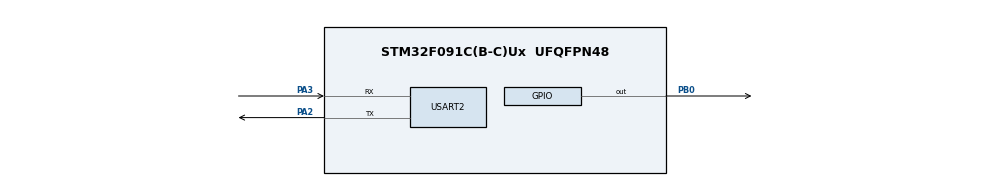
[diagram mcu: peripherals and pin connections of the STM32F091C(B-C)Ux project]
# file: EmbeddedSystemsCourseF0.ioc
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FREERTOS.INCLUDE_vTaskDelayUntil=1
FREERTOS.Tasks01=defaultTask,0,128,startDefaultTask,Default,NULL,Dynamic,NULL,NULL
FREERTOS.Timers01=periodicTimer,periodicTimerCallback,osTimerPeriodic,Default,NULL,Dynamic,NULL;OneShotTimer,OneShotTimerCallback,osTimerOnce,Default,NULL,Dynamic,NULL
FREERTOS.configUSE_IDLE_HOOK=1
FREERTOS.configUSE_NEWLIB_REENTRANT=1
FREERTOS.configUSE_TIMERS=1
Mcu.Family=STM32F0
Mcu.Name=STM32F091C(B-C)Ux
Mcu.Package=UFQFPN48
NVIC.TIM6_DAC_IRQn=true\:3\:0\:false\:false\:true\:false\:false\:true\:true
NVIC.TimeBase=TIM6_DAC_IRQn
NVIC.TimeBaseIP=TIM6
PA2.Mode=Asynchronous
PA2.Signal=USART2_TX
PA3.Mode=Asynchronous
PA3.Signal=USART2_RX
PB0.Signal=GPIO_Output
ProjectManager.HeapSize=0x200
ProjectManager.StackSize=0x400
ProjectManager.TargetToolchain=STM32CubeIDE
USART2.VirtualMode-Asynchronous=VM_ASYNC
VP_FREERTOS_VS_CMSIS_V1.Mode=CMSIS_V1
VP_SYS_VS_tim6.Mode=TIM6
board=custom

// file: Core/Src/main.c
/* USER CODE BEGIN Header */
/**
 ******************************************************************************
 * @file           : main.c
 * @brief          : Main program body
 ******************************************************************************
 * @attention
 *
 * Copyright (c) 2025 STMicroelectronics.
 * All rights reserved.
 *
 * This software is licensed under terms that can be found in the LICENSE file
 * in the root directory of this software component.
 * If no LICENSE file comes with this software, it is provided AS-IS.
 *
 ******************************************************************************
 */
/* USER CODE END Header */
#include "main.h"
#include "cmsis_os.h"

/* USER CODE BEGIN Includes */
#include <stdio.h>
/* USER CODE END Includes */

UART_HandleTypeDef huart2;

osThreadId defaultTaskHandle;
osTimerId periodicTimerHandle;
osTimerId OneShotTimerHandle;
/* USER CODE BEGIN PV */
uint32_t indx = 0;
/* USER CODE END PV */

void SystemClock_Config(void);
static void MX_GPIO_Init(void);
static void MX_USART2_UART_Init(void);
void startDefaultTask(void const * argument);
void periodicTimerCallback(void const * argument);
void OneShotTimerCallback(void const * argument);

/* USER CODE BEGIN PFP */
/*To make printf() work over UART in STM32, we override(Redirected to UART)*/
int _write(int file, char *ptr, int len) {
	HAL_UART_Transmit(&huart2, (uint8_t*) ptr, len, 100);
	return len;
}
/* USER CODE END PFP */

int main(void)
{

  /* MCU Configuration--------------------------------------------------------*/

  /* Reset of all peripherals, Initializes the Flash interface and the Systick. */
  HAL_Init();

  /* Configure the system clock */
  SystemClock_Config();

  /* Initialize all configured peripherals */
  MX_GPIO_Init();
  MX_USART2_UART_Init();

  /* Create the timer(s) */
  /* definition and creation of periodicTimer */
  osTimerDef(periodicTimer, periodicTimerCallback);
  periodicTimerHandle = osTimerCreate(osTimer(periodicTimer), osTimerPeriodic, NULL);

  /* definition and creation of OneShotTimer */
  osTimerDef(OneShotTimer, OneShotTimerCallback);
  OneShotTimerHandle = osTimerCreate(osTimer(OneShotTimer), osTimerOnce, NULL);

  /* USER CODE BEGIN RTOS_TIMERS */
	/* start timers, add new ones, ... */
  /*Start the Timers*/
      if (OneShotTimerHandle != NULL) {
          osTimerStart(OneShotTimerHandle, 2000);  // 2000ms = 2s
      }

      if (periodicTimerHandle != NULL) {
          osTimerStart(periodicTimerHandle, 500);  // 500ms
      }
  /* USER CODE END RTOS_TIMERS */

  /* Create the thread(s) */
  /* definition and creation of defaultTask */
  osThreadDef(defaultTask, startDefaultTask, osPriorityNormal, 0, 128);
  defaultTaskHandle = osThreadCreate(osThread(defaultTask), NULL);

  /* Start scheduler */
  osKernelStart();

  /* We should never get here as control is now taken by the scheduler */
  /* Infinite loop */
	while (1) {

	}
}

void SystemClock_Config(void)
{
  RCC_OscInitTypeDef RCC_OscInitStruct = {0};
  RCC_ClkInitTypeDef RCC_ClkInitStruct = {0};
  RCC_PeriphCLKInitTypeDef PeriphClkInit = {0};

  /** Initializes the RCC Oscillators according to the specified parameters
  * in the RCC_OscInitTypeDef structure.
  */
  RCC_OscInitStruct.OscillatorType = RCC_OSCILLATORTYPE_HSI;
  RCC_OscInitStruct.HSIState = RCC_HSI_ON;
  RCC_OscInitStruct.HSICalibrationValue = RCC_HSICALIBRATION_DEFAULT;
  RCC_OscInitStruct.PLL.PLLState = RCC_PLL_NONE;
  if (HAL_RCC_OscConfig(&RCC_OscInitStruct) != HAL_OK)
  {
    Error_Handler();
  }

  /** Initializes the CPU, AHB and APB buses clocks
  */
  RCC_ClkInitStruct.ClockType = RCC_CLOCKTYPE_HCLK|RCC_CLOCKTYPE_SYSCLK
                              |RCC_CLOCKTYPE_PCLK1;
  RCC_ClkInitStruct.SYSCLKSource = RCC_SYSCLKSOURCE_HSI;
  RCC_ClkInitStruct.AHBCLKDivider = RCC_SYSCLK_DIV1;
  RCC_ClkInitStruct.APB1CLKDivider = RCC_HCLK_DIV1;

  if (HAL_RCC_ClockConfig(&RCC_ClkInitStruct, FLASH_LATENCY_0) != HAL_OK)
  {
    Error_Handler();
  }
  PeriphClkInit.PeriphClockSelection = RCC_PERIPHCLK_USART2;
  PeriphClkInit.Usart2ClockSelection = RCC_USART2CLKSOURCE_PCLK1;
  if (HAL_RCCEx_PeriphCLKConfig(&PeriphClkInit) != HAL_OK)
  {
    Error_Handler();
  }
}

static void MX_USART2_UART_Init(void)
{

  huart2.Instance = USART2;
  huart2.Init.BaudRate = 115200;
  huart2.Init.WordLength = UART_WORDLENGTH_8B;
  huart2.Init.StopBits = UART_STOPBITS_1;
  huart2.Init.Parity = UART_PARITY_NONE;
  huart2.Init.Mode = UART_MODE_TX_RX;
  huart2.Init.HwFlowCtl = UART_HWCONTROL_NONE;
  huart2.Init.OverSampling = UART_OVERSAMPLING_16;
  huart2.Init.OneBitSampling = UART_ONE_BIT_SAMPLE_DISABLE;
  huart2.AdvancedInit.AdvFeatureInit = UART_ADVFEATURE_NO_INIT;
  if (HAL_UART_Init(&huart2) != HAL_OK)
  {
    Error_Handler();
  }

}

static void MX_GPIO_Init(void)
{
  GPIO_InitTypeDef GPIO_InitStruct = {0};

  /* GPIO Ports Clock Enable */
  __HAL_RCC_GPIOA_CLK_ENABLE();
  __HAL_RCC_GPIOB_CLK_ENABLE();

  /*Configure GPIO pin Output Level */
  HAL_GPIO_WritePin(GPIOB, GPIO_PIN_0, GPIO_PIN_RESET);

  /*Configure GPIO pin : PB0 */
  GPIO_InitStruct.Pin = GPIO_PIN_0;
  GPIO_InitStruct.Mode = GPIO_MODE_OUTPUT_PP;
  GPIO_InitStruct.Pull = GPIO_NOPULL;
  GPIO_InitStruct.Speed = GPIO_SPEED_FREQ_LOW;
  HAL_GPIO_Init(GPIOB, &GPIO_InitStruct);

}

void startDefaultTask(void const * argument)
{
	for (;;) {
		osDelay(1);
	}
}

/* periodicTimerCallback function */
void periodicTimerCallback(void const * argument)
{
  /* USER CODE BEGIN periodicTimerCallback */
	   printf("\rPeriodic Timer Expired! Blinking LED...\n");
	    HAL_GPIO_TogglePin(GPIOB, GPIO_PIN_0);  // Toggle LED on PB0!
  /* USER CODE END periodicTimerCallback */
}

/* OneShotTimerCallback function */
void OneShotTimerCallback(void const * argument)
{
  /* USER CODE BEGIN OneShotTimerCallback */
	 printf("\rOne-Shot Timer Expired!\n");
  /* USER CODE END OneShotTimerCallback */
}

void HAL_TIM_PeriodElapsedCallback(TIM_HandleTypeDef *htim)
{
  if (htim->Instance == TIM6) {
    HAL_IncTick();
  }
}

void Error_Handler(void)
{
	__disable_irq();
	while (1) {
	}
}

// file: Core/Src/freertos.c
/* USER CODE BEGIN Header */
/**
  ******************************************************************************
  * File Name          : freertos.c
  * Description        : Code for freertos applications
  ******************************************************************************
  * @attention
  *
  * Copyright (c) 2025 STMicroelectronics.
  * All rights reserved.
  *
  * This software is licensed under terms that can be found in the LICENSE file
  * in the root directory of this software component.
  * If no LICENSE file comes with this software, it is provided AS-IS.
  *
  ******************************************************************************
  */
/* USER CODE END Header */

#include "FreeRTOS.h"
#include "task.h"
#include "main.h"

/* GetIdleTaskMemory prototype (linked to static allocation support) */
void vApplicationGetIdleTaskMemory( StaticTask_t **ppxIdleTaskTCBBuffer, StackType_t **ppxIdleTaskStackBuffer, uint32_t *pulIdleTaskStackSize );

/* GetTimerTaskMemory prototype (linked to static allocation support) */
void vApplicationGetTimerTaskMemory( StaticTask_t **ppxTimerTaskTCBBuffer, StackType_t **ppxTimerTaskStackBuffer, uint32_t *pulTimerTaskStackSize );

/* Hook prototypes */
void vApplicationIdleHook(void);

/* USER CODE BEGIN 2 */
__weak void vApplicationIdleHook( void )
{
   /* vApplicationIdleHook() will only be called if configUSE_IDLE_HOOK is set
   to 1 in FreeRTOSConfig.h. It will be called on each iteration of the idle
   task. It is essential that code added to this hook function never attempts
   to block in any way (for example, call xQueueReceive() with a block time
   specified, or call vTaskDelay()). If the application makes use of the
   vTaskDelete() API function (as this demo application does) then it is also
   important that vApplicationIdleHook() is permitted to return to its calling
   function, because it is the responsibility of the idle task to clean up
   memory allocated by the kernel to any task that has since been deleted. */
}
/* USER CODE END 2 */

/* USER CODE BEGIN GET_IDLE_TASK_MEMORY */
static StaticTask_t xIdleTaskTCBBuffer;
static StackType_t xIdleStack[configMINIMAL_STACK_SIZE];

void vApplicationGetIdleTaskMemory( StaticTask_t **ppxIdleTaskTCBBuffer, StackType_t **ppxIdleTaskStackBuffer, uint32_t *pulIdleTaskStackSize )
{
  *ppxIdleTaskTCBBuffer = &xIdleTaskTCBBuffer;
  *ppxIdleTaskStackBuffer = &xIdleStack[0];
  *pulIdleTaskStackSize = configMINIMAL_STACK_SIZE;
  /* place for user code */
}
/* USER CODE END GET_IDLE_TASK_MEMORY */

/* USER CODE BEGIN GET_TIMER_TASK_MEMORY */
static StaticTask_t xTimerTaskTCBBuffer;
static StackType_t xTimerStack[configTIMER_TASK_STACK_DEPTH];

void vApplicationGetTimerTaskMemory( StaticTask_t **ppxTimerTaskTCBBuffer, StackType_t **ppxTimerTaskStackBuffer, uint32_t *pulTimerTaskStackSize )
{
  *ppxTimerTaskTCBBuffer = &xTimerTaskTCBBuffer;
  *ppxTimerTaskStackBuffer = &xTimerStack[0];
  *pulTimerTaskStackSize = configTIMER_TASK_STACK_DEPTH;
  /* place for user code */
}
/* USER CODE END GET_TIMER_TASK_MEMORY */
